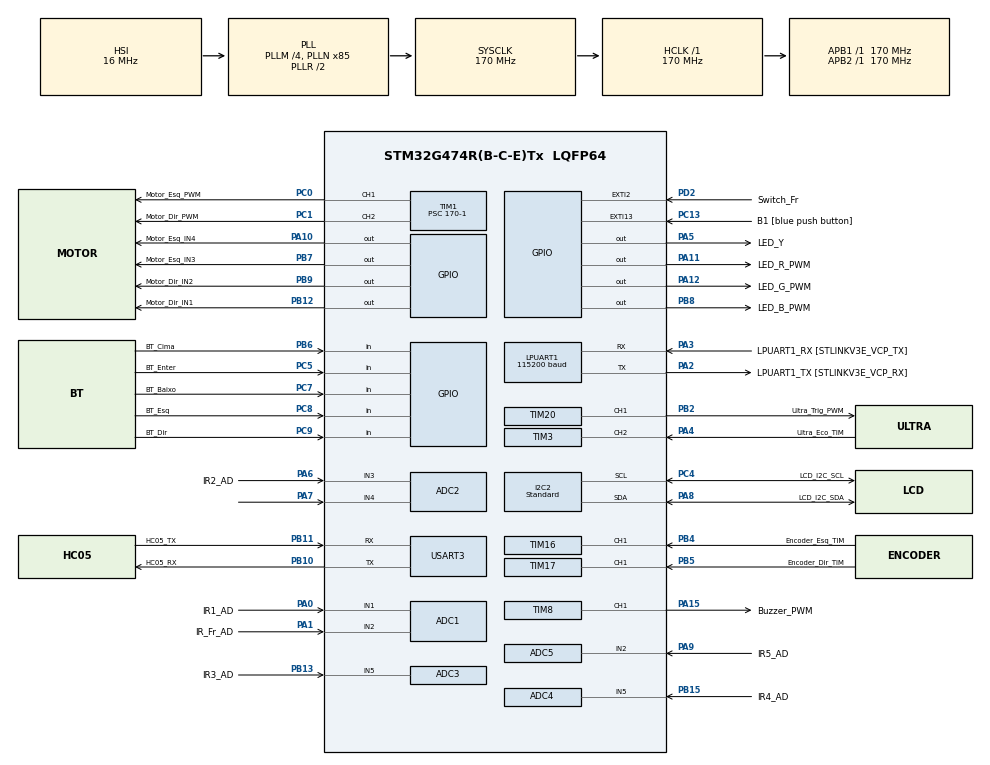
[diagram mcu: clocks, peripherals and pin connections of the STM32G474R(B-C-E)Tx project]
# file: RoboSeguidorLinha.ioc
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ADC1.Channel-0\#ChannelRegularConversion=ADC_CHANNEL_1
ADC1.Channel-1\#ChannelRegularConversion=ADC_CHANNEL_2
ADC1.ContinuousConvMode=ENABLE
ADC1.DMAContinuousRequests=ENABLE
ADC1.EOCSelection=ADC_EOC_SEQ_CONV
ADC1.NbrOfConversion=2
ADC1.NbrOfConversionFlag=1
ADC1.OffsetNumber-0\#ChannelRegularConversion=ADC_OFFSET_NONE
ADC1.OffsetNumber-1\#ChannelRegularConversion=ADC_OFFSET_NONE
ADC1.Overrun=ADC_OVR_DATA_OVERWRITTEN
ADC1.OversamplingMode=ENABLE
ADC1.Rank-0\#ChannelRegularConversion=1
ADC1.Rank-1\#ChannelRegularConversion=2
ADC1.Ratio=ADC_OVERSAMPLING_RATIO_128
ADC1.RightBitShift=ADC_RIGHTBITSHIFT_7
ADC1.SamplingTime-0\#ChannelRegularConversion=ADC_SAMPLETIME_47CYCLES_5
ADC1.SamplingTime-1\#ChannelRegularConversion=ADC_SAMPLETIME_47CYCLES_5
ADC1.master=1
ADC2.Channel-1\#ChannelRegularConversion=ADC_CHANNEL_3
ADC2.ContinuousConvMode=DISABLE
ADC2.DMAContinuousRequests=ENABLE
ADC2.EOCSelection=ADC_EOC_SINGLE_CONV
ADC2.NbrOfConversion=1
ADC2.NbrOfConversionFlag=1
ADC2.OffsetNumber-1\#ChannelRegularConversion=ADC_OFFSET_NONE
ADC2.OversamplingMode=ENABLE
ADC2.Rank-1\#ChannelRegularConversion=1
ADC2.Ratio=ADC_OVERSAMPLING_RATIO_128
ADC2.RightBitShift=ADC_RIGHTBITSHIFT_3
ADC2.SamplingTime-1\#ChannelRegularConversion=ADC_SAMPLETIME_47CYCLES_5
ADC3.Channel-0\#ChannelRegularConversion=ADC_CHANNEL_5
ADC3.ContinuousConvMode=ENABLE
ADC3.DMAContinuousRequests=ENABLE
ADC3.EOCSelection=ADC_EOC_SEQ_CONV
ADC3.NbrOfConversionFlag=1
ADC3.OffsetNumber-0\#ChannelRegularConversion=ADC_OFFSET_NONE
ADC3.OversamplingMode=ENABLE
ADC3.Rank-0\#ChannelRegularConversion=1
ADC3.Ratio=ADC_OVERSAMPLING_RATIO_128
ADC3.RightBitShift=ADC_RIGHTBITSHIFT_7
ADC3.SamplingTime-0\#ChannelRegularConversion=ADC_SAMPLETIME_47CYCLES_5
ADC3.master=1
ADC4.Channel-0\#ChannelRegularConversion=ADC_CHANNEL_5
ADC4.ContinuousConvMode=ENABLE
ADC4.DMAContinuousRequests=ENABLE
ADC4.NbrOfConversionFlag=1
ADC4.OffsetNumber-0\#ChannelRegularConversion=ADC_OFFSET_NONE
ADC4.OversamplingMode=ENABLE
ADC4.Rank-0\#ChannelRegularConversion=1
ADC4.Ratio=ADC_OVERSAMPLING_RATIO_128
ADC4.RightBitShift=ADC_RIGHTBITSHIFT_7
ADC4.SamplingTime-0\#ChannelRegularConversion=ADC_SAMPLETIME_2CYCLES_5
ADC5.Channel-0\#ChannelRegularConversion=ADC_CHANNEL_2
ADC5.ContinuousConvMode=ENABLE
ADC5.DMAContinuousRequests=ENABLE
ADC5.EOCSelection=ADC_EOC_SEQ_CONV
ADC5.NbrOfConversionFlag=1
ADC5.OffsetNumber-0\#ChannelRegularConversion=ADC_OFFSET_NONE
ADC5.OversamplingMode=ENABLE
ADC5.Rank-0\#ChannelRegularConversion=1
ADC5.Ratio=ADC_OVERSAMPLING_RATIO_128
ADC5.RightBitShift=ADC_RIGHTBITSHIFT_7
ADC5.SamplingTime-0\#ChannelRegularConversion=ADC_SAMPLETIME_47CYCLES_5
Dma.ADC1.0.Direction=DMA_PERIPH_TO_MEMORY
Dma.ADC1.0.EventEnable=DISABLE
Dma.ADC1.0.Instance=DMA1_Channel1
Dma.ADC1.0.MemDataAlignment=DMA_MDATAALIGN_HALFWORD
Dma.ADC1.0.MemInc=DMA_MINC_ENABLE
Dma.ADC1.0.Mode=DMA_CIRCULAR
Dma.ADC1.0.PeriphDataAlignment=DMA_PDATAALIGN_HALFWORD
Dma.ADC1.0.PeriphInc=DMA_PINC_DISABLE
Dma.ADC1.0.Polarity=HAL_DMAMUX_REQ_GEN_RISING
Dma.ADC1.0.Priority=DMA_PRIORITY_LOW
Dma.ADC1.0.RequestNumber=1
Dma.ADC1.0.SignalID=NONE
Dma.ADC1.0.SyncEnable=DISABLE
Dma.ADC1.0.SyncPolarity=HAL_DMAMUX_SYNC_NO_EVENT
Dma.ADC1.0.SyncRequestNumber=1
Dma.ADC1.0.SyncSignalID=NONE
Dma.ADC2.3.Direction=DMA_PERIPH_TO_MEMORY
Dma.ADC2.3.EventEnable=DISABLE
Dma.ADC2.3.Instance=DMA1_Channel2
Dma.ADC2.3.MemDataAlignment=DMA_MDATAALIGN_HALFWORD
Dma.ADC2.3.MemInc=DMA_MINC_ENABLE
Dma.ADC2.3.Mode=DMA_CIRCULAR
Dma.ADC2.3.PeriphDataAlignment=DMA_PDATAALIGN_HALFWORD
Dma.ADC2.3.PeriphInc=DMA_PINC_DISABLE
Dma.ADC2.3.Polarity=HAL_DMAMUX_REQ_GEN_RISING
Dma.ADC2.3.Priority=DMA_PRIORITY_LOW
Dma.ADC2.3.RequestNumber=1
Dma.ADC2.3.SignalID=NONE
Dma.ADC2.3.SyncEnable=DISABLE
Dma.ADC2.3.SyncPolarity=HAL_DMAMUX_SYNC_NO_EVENT
Dma.ADC2.3.SyncRequestNumber=1
Dma.ADC2.3.SyncSignalID=NONE
Dma.ADC3.1.Direction=DMA_PERIPH_TO_MEMORY
Dma.ADC3.1.EventEnable=DISABLE
Dma.ADC3.1.Instance=DMA1_Channel3
Dma.ADC3.1.MemDataAlignment=DMA_MDATAALIGN_HALFWORD
Dma.ADC3.1.MemInc=DMA_MINC_ENABLE
Dma.ADC3.1.Mode=DMA_CIRCULAR
Dma.ADC3.1.PeriphDataAlignment=DMA_PDATAALIGN_HALFWORD
Dma.ADC3.1.PeriphInc=DMA_PINC_DISABLE
Dma.ADC3.1.Polarity=HAL_DMAMUX_REQ_GEN_RISING
Dma.ADC3.1.Priority=DMA_PRIORITY_LOW
Dma.ADC3.1.RequestNumber=1
Dma.ADC3.1.SignalID=NONE
Dma.ADC3.1.SyncEnable=DISABLE
Dma.ADC3.1.SyncPolarity=HAL_DMAMUX_SYNC_NO_EVENT
Dma.ADC3.1.SyncRequestNumber=1
Dma.ADC3.1.SyncSignalID=NONE
Dma.ADC4.4.Direction=DMA_PERIPH_TO_MEMORY
Dma.ADC4.4.EventEnable=DISABLE
Dma.ADC4.4.Instance=DMA1_Channel4
Dma.ADC4.4.MemDataAlignment=DMA_MDATAALIGN_HALFWORD
Dma.ADC4.4.MemInc=DMA_MINC_ENABLE
Dma.ADC4.4.Mode=DMA_CIRCULAR
Dma.ADC4.4.PeriphDataAlignment=DMA_PDATAALIGN_HALFWORD
Dma.ADC4.4.PeriphInc=DMA_PINC_DISABLE
Dma.ADC4.4.Polarity=HAL_DMAMUX_REQ_GEN_RISING
Dma.ADC4.4.Priority=DMA_PRIORITY_LOW
Dma.ADC4.4.RequestNumber=1
Dma.ADC4.4.SignalID=NONE
Dma.ADC4.4.SyncEnable=DISABLE
Dma.ADC4.4.SyncPolarity=HAL_DMAMUX_SYNC_NO_EVENT
Dma.ADC4.4.SyncRequestNumber=1
Dma.ADC4.4.SyncSignalID=NONE
Dma.ADC5.2.Direction=DMA_PERIPH_TO_MEMORY
Dma.ADC5.2.EventEnable=DISABLE
Dma.ADC5.2.Instance=DMA1_Channel5
Dma.ADC5.2.MemDataAlignment=DMA_MDATAALIGN_HALFWORD
Dma.ADC5.2.MemInc=DMA_MINC_ENABLE
Dma.ADC5.2.Mode=DMA_CIRCULAR
Dma.ADC5.2.PeriphDataAlignment=DMA_PDATAALIGN_HALFWORD
Dma.ADC5.2.PeriphInc=DMA_PINC_DISABLE
Dma.ADC5.2.Polarity=HAL_DMAMUX_REQ_GEN_RISING
Dma.ADC5.2.Priority=DMA_PRIORITY_LOW
Dma.ADC5.2.RequestNumber=1
Dma.ADC5.2.SignalID=NONE
Dma.ADC5.2.SyncEnable=DISABLE
Dma.ADC5.2.SyncPolarity=HAL_DMAMUX_SYNC_NO_EVENT
Dma.ADC5.2.SyncRequestNumber=1
Dma.ADC5.2.SyncSignalID=NONE
Dma.I2C2_RX.5.Direction=DMA_PERIPH_TO_MEMORY
Dma.I2C2_RX.5.EventEnable=DISABLE
Dma.I2C2_RX.5.Instance=DMA2_Channel6
Dma.I2C2_RX.5.MemDataAlignment=DMA_MDATAALIGN_BYTE
Dma.I2C2_RX.5.MemInc=DMA_MINC_ENABLE
Dma.I2C2_RX.5.Mode=DMA_NORMAL
Dma.I2C2_RX.5.PeriphDataAlignment=DMA_PDATAALIGN_BYTE
Dma.I2C2_RX.5.PeriphInc=DMA_PINC_DISABLE
Dma.I2C2_RX.5.Polarity=HAL_DMAMUX_REQ_GEN_RISING
Dma.I2C2_RX.5.Priority=DMA_PRIORITY_LOW
Dma.I2C2_RX.5.RequestNumber=1
Dma.I2C2_RX.5.SignalID=NONE
Dma.I2C2_RX.5.SyncEnable=DISABLE
Dma.I2C2_RX.5.SyncPolarity=HAL_DMAMUX_SYNC_NO_EVENT
Dma.I2C2_RX.5.SyncRequestNumber=1
Dma.I2C2_RX.5.SyncSignalID=NONE
Dma.I2C2_TX.6.Direction=DMA_MEMORY_TO_PERIPH
Dma.I2C2_TX.6.EventEnable=DISABLE
Dma.I2C2_TX.6.Instance=DMA2_Channel7
Dma.I2C2_TX.6.MemDataAlignment=DMA_MDATAALIGN_BYTE
Dma.I2C2_TX.6.MemInc=DMA_MINC_ENABLE
Dma.I2C2_TX.6.Mode=DMA_NORMAL
Dma.I2C2_TX.6.PeriphDataAlignment=DMA_PDATAALIGN_BYTE
Dma.I2C2_TX.6.PeriphInc=DMA_PINC_DISABLE
Dma.I2C2_TX.6.Polarity=HAL_DMAMUX_REQ_GEN_RISING
Dma.I2C2_TX.6.Priority=DMA_PRIORITY_LOW
Dma.I2C2_TX.6.RequestNumber=1
Dma.I2C2_TX.6.SignalID=NONE
Dma.I2C2_TX.6.SyncEnable=DISABLE
Dma.I2C2_TX.6.SyncPolarity=HAL_DMAMUX_SYNC_NO_EVENT
Dma.I2C2_TX.6.SyncRequestNumber=1
Dma.I2C2_TX.6.SyncSignalID=NONE
Dma.Request0=ADC1
Dma.Request1=ADC3
Dma.Request2=ADC5
Dma.Request3=ADC2
Dma.Request4=ADC4
Dma.Request5=I2C2_RX
Dma.Request6=I2C2_TX
FREERTOS.BinarySemaphores01=Sem_Colisao,Dynamic,NULL
FREERTOS.Mutexes01=Mutex_Sensores,Dynamic,NULL;Mutex_Odometria,Dynamic,NULL;Mutex_PID,Dynamic,NULL;Mutex_Battery,Dynamic,NULL
FREERTOS.Queues01=Queue_Comandos,16,uint16_t,0,Dynamic,NULL,NULL
FREERTOS.Tasks01=task_main,24,256,task_Main,Default,NULL,Dynamic,NULL,NULL;task_controle,40,512,task_Controle,As external,NULL,Dynamic,NULL,NULL;task_sensores,8,256,task_Sensores,As external,NULL,Dynamic,NULL,NULL;task_odometria,8,256,task_Odometria,As external,NULL,Dynamic,NULL,NULL;task_bluetooth,16,256,task_Bluetooth,As external,NULL,Dynamic,NULL,NULL;task_LVBateria,8,128,task_LvBateria,As external,NULL,Dynamic,NULL,NULL;task_Display,8,128,task_display,As external,NULL,Dynamic,NULL,NULL;task_linhas,8,128,task_Linhas,Default,NULL,Dynamic,NULL,NULL
FREERTOS.configTOTAL_HEAP_SIZE=10240
FREERTOS.configUSE_NEWLIB_REENTRANT=1
I2C2.I2C_Speed_Mode=I2C_Standard
I2C2.Timing=0x30A0A7FB
LPUART1.BaudRate=115200
LPUART1.WordLength=UART_WORDLENGTH_8B
Mcu.Family=STM32G4
Mcu.Name=STM32G474R(B-C-E)Tx
Mcu.Package=LQFP64
NVIC.ADC1_2_IRQn=true\:5\:0\:false\:false\:true\:true\:true\:true\:true
NVIC.ADC3_IRQn=true\:5\:0\:false\:false\:true\:true\:true\:true\:true
NVIC.ADC4_IRQn=true\:5\:0\:false\:false\:true\:true\:true\:true\:true
NVIC.ADC5_IRQn=true\:5\:0\:false\:false\:true\:true\:true\:true\:true
NVIC.DMA1_Channel1_IRQn=true\:5\:0\:false\:false\:true\:true\:false\:true\:true
NVIC.DMA1_Channel2_IRQn=true\:5\:0\:false\:false\:true\:true\:false\:true\:true
NVIC.DMA1_Channel3_IRQn=true\:5\:0\:false\:false\:true\:true\:false\:true\:true
NVIC.DMA1_Channel4_IRQn=true\:5\:0\:false\:false\:true\:true\:false\:true\:true
NVIC.DMA1_Channel5_IRQn=true\:5\:0\:false\:false\:true\:true\:false\:true\:true
NVIC.DMA2_Channel6_IRQn=true\:5\:0\:false\:false\:true\:true\:false\:true\:true
NVIC.DMA2_Channel7_IRQn=true\:5\:0\:false\:false\:true\:false\:false\:true\:true
NVIC.EXTI15_10_IRQn=true\:5\:0\:false\:false\:true\:true\:true\:true\:true
NVIC.EXTI2_IRQn=true\:5\:0\:false\:false\:true\:true\:true\:true\:true
NVIC.I2C2_ER_IRQn=true\:5\:0\:false\:false\:true\:true\:true\:true\:true
NVIC.I2C2_EV_IRQn=true\:5\:0\:false\:false\:true\:true\:true\:true\:true
NVIC.PriorityGroup=NVIC_PRIORITYGROUP_4
NVIC.TIM1_TRG_COM_TIM17_IRQn=true\:5\:0\:false\:false\:true\:true\:true\:true\:true
NVIC.TIM1_UP_TIM16_IRQn=true\:5\:0\:false\:false\:true\:true\:true\:true\:true
NVIC.TIM3_IRQn=true\:5\:0\:false\:false\:true\:true\:true\:true\:true
NVIC.TIM6_DAC_IRQn=true\:15\:0\:false\:false\:true\:false\:false\:true\:true
NVIC.TimeBase=TIM6_DAC_IRQn
NVIC.TimeBaseIP=TIM6
NVIC.USART3_IRQn=true\:5\:0\:false\:false\:true\:true\:true\:true\:true
PA0.GPIO_Label=IR1_AD
PA0.Mode=IN1-Single-Ended
PA0.Signal=ADC1_IN1
PA1.GPIO_Label=IR_Fr_AD
PA1.Mode=IN2-Single-Ended
PA1.Signal=ADC1_IN2
PA10.GPIO_Label=Motor_Esq_IN4
PA10.Signal=GPIO_Output
PA11.GPIO_Label=LED_R_PWM
PA11.Signal=GPIO_Output
PA12.GPIO_Label=LED_G_PWM
PA12.Signal=GPIO_Output
PA13.GPIO_Label=T_SWDIO
PA13.Mode=Serial_Wire
PA13.Signal=SYS_JTMS-SWDIO
PA14.GPIO_Label=T_SWCLK
PA14.Mode=Serial_Wire
PA14.Signal=SYS_JTCK-SWCLK
PA15.GPIO_Label=Buzzer_PWM
PA15.Signal=S_TIM8_CH1
PA2.GPIO_Label=LPUART1_TX [STLINKV3E_VCP_RX]
PA2.Mode=Asynchronous
PA2.Signal=LPUART1_TX
PA3.GPIO_Label=LPUART1_RX [STLINKV3E_VCP_TX]
PA3.Mode=Asynchronous
PA3.Signal=LPUART1_RX
PA4.GPIO_Label=Ultra_Eco_TIM
PA4.Signal=S_TIM3_CH2
PA5.GPIO_Label=LED_Y
PA5.Signal=GPIO_Output
PA6.GPIO_Label=IR2_AD
PA6.Mode=IN3-Single-Ended
PA6.Signal=ADC2_IN3
PA7.Signal=SharedAnalog_PA7
PA8.GPIO_Label=LCD_I2C_SDA
PA8.Mode=I2C
PA8.Signal=I2C2_SDA
PA9.GPIO_Label=IR5_AD
PA9.Mode=IN2-Single-Ended
PA9.Signal=ADC5_IN2
PB10.GPIO_Label=HC05_RX
PB10.Mode=Asynchronous
PB10.Signal=USART3_TX
PB11.GPIO_Label=HC05_TX
PB11.Mode=Asynchronous
PB11.Signal=USART3_RX
PB12.GPIO_Label=Motor_Dir_IN1
PB12.Signal=GPIO_Output
PB13.GPIO_Label=IR3_AD
PB13.Mode=IN5-Single-Ended
PB13.Signal=ADC3_IN5
PB15.GPIO_Label=IR4_AD
PB15.Mode=IN5-Single-Ended
PB15.Signal=ADC4_IN5
PB2.GPIO_Label=Ultra_Trig_PWM
PB2.Mode=Output Compare1 CH1
PB2.Signal=TIM20_CH1
PB3.GPIO_Label=T_SWO
PB3.Signal=SYS_JTDO-SWO
PB4.GPIO_Label=Encoder_Esq_TIM
PB4.Signal=S_TIM16_CH1
PB5.GPIO_Label=Encoder_Dir_TIM
PB5.Signal=S_TIM17_CH1
PB6.GPIO_Label=BT_Cima
PB6.Signal=GPIO_Input
PB7.GPIO_Label=Motor_Esq_IN3
PB7.Signal=GPIO_Output
PB8-BOOT0.GPIO_Label=LED_B_PWM
PB8-BOOT0.Signal=GPIO_Output
PB9.GPIO_Label=Motor_Dir_IN2
PB9.Signal=GPIO_Output
PC0.GPIO_Label=Motor_Esq_PWM
PC0.Signal=S_TIM1_CH1
PC1.GPIO_Label=Motor_Dir_PWM
PC1.Signal=S_TIM1_CH2
PC13.GPIO_Label=B1 [blue push button]
PC13.Signal=GPXTI13
PC14-OSC32_IN.Mode=LSE-External-Oscillator
PC14-OSC32_IN.Signal=RCC_OSC32_IN
PC15-OSC32_OUT.Mode=LSE-External-Oscillator
PC15-OSC32_OUT.Signal=RCC_OSC32_OUT
PC4.GPIO_Label=LCD_I2C_SCL
PC4.Mode=I2C
PC4.Signal=I2C2_SCL
PC5.GPIO_Label=BT_Enter
PC5.GPIO_PuPd=GPIO_PULLUP
PC5.Signal=GPIO_Input
PC7.GPIO_Label=BT_Baixo
PC7.Signal=GPIO_Input
PC8.GPIO_Label=BT_Esq
PC8.Signal=GPIO_Input
PC9.GPIO_Label=BT_Dir
PC9.Signal=GPIO_Input
PD2.GPIO_Label=Switch_Fr
PD2.GPIO_ModeDefaultEXTI=GPIO_MODE_IT_FALLING
PD2.GPIO_PuPd=GPIO_PULLUP
PD2.Signal=GPXTI2
PF0-OSC_IN.Mode=HSE-External-Oscillator
PF0-OSC_IN.Signal=RCC_OSC_IN
PF1-OSC_OUT.Mode=HSE-External-Oscillator
PF1-OSC_OUT.Signal=RCC_OSC_OUT
ProjectManager.HeapSize=0x200
ProjectManager.StackSize=0x400
ProjectManager.TargetToolchain=STM32CubeIDE
RCC.ADC12Freq_Value=170000000
RCC.ADC345Freq_Value=170000000
RCC.AHBFreq_Value=170000000
RCC.APB1Freq_Value=170000000
RCC.APB1TimFreq_Value=170000000
RCC.APB2Freq_Value=170000000
RCC.APB2TimFreq_Value=170000000
RCC.CortexFreq_Value=170000000
RCC.EXTERNAL_CLOCK_VALUE=12288000
RCC.HCLKFreq_Value=170000000
RCC.HSE_VALUE=24000000
RCC.HSI48_VALUE=48000000
RCC.HSI_VALUE=16000000
RCC.PLLM=RCC_PLLM_DIV4
RCC.PLLN=85
RCC.RTCClockSelection=RCC_RTCCLKSOURCE_LSE
RCC.SYSCLKFreq_VALUE=170000000
RCC.SYSCLKSource=RCC_SYSCLKSOURCE_PLLCLK
RCC.USBFreq_Value=170000000
RCC.VCOOutputFreq_Value=340000000
SH.S_TIM16_CH1.0=TIM16_CH1,Input_Capture1_from_TI1
SH.S_TIM17_CH1.0=TIM17_CH1,Input_Capture1_from_TI1
SH.S_TIM1_CH1.0=TIM1_CH1,PWM Generation1 CH1
SH.S_TIM1_CH2.0=TIM1_CH2,PWM Generation2 CH2
SH.S_TIM3_CH2.0=TIM3_CH2,Input_Capture2_from_TI2
SH.S_TIM8_CH1.0=TIM8_CH1,PWM Generation1 CH1
SH.SharedAnalog_PA7.0=ADC2_IN4,IN4-Single-Ended
SH.SharedAnalog_PA7.1=OPAMP2_VINP,PGA_Internally_Connected
SH.SharedAnalog_PA7.2=OPAMP1_VINP,PGA_Internally_Connected
TIM1.Channel-PWM\ Generation1\ CH1=TIM_CHANNEL_1
TIM1.Channel-PWM\ Generation2\ CH2=TIM_CHANNEL_2
TIM1.PeriodNoDither=100-1
TIM1.Prescaler=170-1
TIM16.Channel=TIM_CHANNEL_1
TIM17.Channel=TIM_CHANNEL_1
TIM20.Channel-Output\ Compare1\ CH1=TIM_CHANNEL_1
TIM3.Channel-Input_Capture2_from_TI2=TIM_CHANNEL_2
TIM3.PeriodNoDither=100-1
TIM3.Prescaler=170-1
TIM8.Channel-PWM\ Generation1\ CH1=TIM_CHANNEL_1
TIM8.PeriodNoDither=1000-1
TIM8.Prescaler=170-1
USART3.VirtualMode-Asynchronous=VM_ASYNC
VP_ADC2_OPAMP_INTERNAL2.Mode=IN-OPAMP2
VP_FREERTOS_VS_CMSIS_V2.Mode=CMSIS_V2
VP_SYS_VS_DBSignals.Mode=DisableDeadBatterySignals
VP_SYS_VS_tim6.Mode=TIM6
VP_TIM16_VS_ClockSourceINT.Mode=Enable_Timer
VP_TIM17_VS_ClockSourceINT.Mode=Enable_Timer
VP_TIM1_VS_ClockSourceINT.Mode=Internal
VP_TIM20_VS_ClockSourceINT.Mode=Internal
VP_TIM2_VS_ClockSourceINT.Mode=Internal
VP_TIM3_VS_ClockSourceINT.Mode=Internal
VP_TIM8_VS_ClockSourceINT.Mode=Internal
board=NUCLEO-G474RE

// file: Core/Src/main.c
/* USER CODE BEGIN Header */
/**
  ******************************************************************************
  * @file           : main.c
  * @brief          : Main program body
  ******************************************************************************
  * @attention
  *
  * Copyright (c) 2026 STMicroelectronics.
  * All rights reserved.
  *
  * This software is licensed under terms that can be found in the LICENSE file
  * in the root directory of this software component.
  * If no LICENSE file comes with this software, it is provided AS-IS.
  *
  ******************************************************************************
  */
/* USER CODE END Header */
#include "main.h"
#include "cmsis_os.h"

/* USER CODE BEGIN Includes */
#include "lineSensors_v2.h"
#include "motorEncoder.h"

/* USER CODE END Includes */

ADC_HandleTypeDef hadc1;
ADC_HandleTypeDef hadc2;
ADC_HandleTypeDef hadc3;
ADC_HandleTypeDef hadc4;
ADC_HandleTypeDef hadc5;
DMA_HandleTypeDef hdma_adc1;
DMA_HandleTypeDef hdma_adc2;
DMA_HandleTypeDef hdma_adc3;
DMA_HandleTypeDef hdma_adc4;
DMA_HandleTypeDef hdma_adc5;

I2C_HandleTypeDef hi2c2;
DMA_HandleTypeDef hdma_i2c2_rx;
DMA_HandleTypeDef hdma_i2c2_tx;

UART_HandleTypeDef hlpuart1;
UART_HandleTypeDef huart3;

OPAMP_HandleTypeDef hopamp1;
OPAMP_HandleTypeDef hopamp2;

TIM_HandleTypeDef htim1;
TIM_HandleTypeDef htim2;
TIM_HandleTypeDef htim3;
TIM_HandleTypeDef htim8;
TIM_HandleTypeDef htim16;
TIM_HandleTypeDef htim17;
TIM_HandleTypeDef htim20;

/* Definitions for task_main */
osThreadId_t task_mainHandle;
const osThreadAttr_t task_main_attributes = {
  .name = "task_main",
  .priority = (osPriority_t) osPriorityNormal,
  .stack_size = 256 * 4
};
/* Definitions for task_controle */
osThreadId_t task_controleHandle;
const osThreadAttr_t task_controle_attributes = {
  .name = "task_controle",
  .priority = (osPriority_t) osPriorityHigh,
  .stack_size = 512 * 4
};
/* Definitions for task_sensores */
osThreadId_t task_sensoresHandle;
const osThreadAttr_t task_sensores_attributes = {
  .name = "task_sensores",
  .priority = (osPriority_t) osPriorityLow,
  .stack_size = 256 * 4
};
/* Definitions for task_odometria */
osThreadId_t task_odometriaHandle;
const osThreadAttr_t task_odometria_attributes = {
  .name = "task_odometria",
  .priority = (osPriority_t) osPriorityLow,
  .stack_size = 256 * 4
};
/* Definitions for task_bluetooth */
osThreadId_t task_bluetoothHandle;
const osThreadAttr_t task_bluetooth_attributes = {
  .name = "task_bluetooth",
  .priority = (osPriority_t) osPriorityBelowNormal,
  .stack_size = 256 * 4
};
/* Definitions for task_LVBateria */
osThreadId_t task_LVBateriaHandle;
const osThreadAttr_t task_LVBateria_attributes = {
  .name = "task_LVBateria",
  .priority = (osPriority_t) osPriorityLow,
  .stack_size = 128 * 4
};
/* Definitions for task_Display */
osThreadId_t task_DisplayHandle;
const osThreadAttr_t task_Display_attributes = {
  .name = "task_Display",
  .priority = (osPriority_t) osPriorityLow,
  .stack_size = 128 * 4
};
/* Definitions for task_linhas */
osThreadId_t task_linhasHandle;
const osThreadAttr_t task_linhas_attributes = {
  .name = "task_linhas",
  .priority = (osPriority_t) osPriorityLow,
  .stack_size = 128 * 4
};
/* Definitions for Queue_Comandos */
osMessageQueueId_t Queue_ComandosHandle;
const osMessageQueueAttr_t Queue_Comandos_attributes = {
  .name = "Queue_Comandos"
};
/* Definitions for Mutex_Sensores */
osMutexId_t Mutex_SensoresHandle;
const osMutexAttr_t Mutex_Sensores_attributes = {
  .name = "Mutex_Sensores"
};
/* Definitions for Mutex_Odometria */
osMutexId_t Mutex_OdometriaHandle;
const osMutexAttr_t Mutex_Odometria_attributes = {
  .name = "Mutex_Odometria"
};
/* Definitions for Mutex_PID */
osMutexId_t Mutex_PIDHandle;
const osMutexAttr_t Mutex_PID_attributes = {
  .name = "Mutex_PID"
};
/* Definitions for Mutex_Battery */
osMutexId_t Mutex_BatteryHandle;
const osMutexAttr_t Mutex_Battery_attributes = {
  .name = "Mutex_Battery"
};
/* Definitions for Sem_Colisao */
osSemaphoreId_t Sem_ColisaoHandle;
const osSemaphoreAttr_t Sem_Colisao_attributes = {
  .name = "Sem_Colisao"
};

void SystemClock_Config(void);
static void MX_GPIO_Init(void);
static void MX_DMA_Init(void);
static void MX_LPUART1_UART_Init(void);
static void MX_ADC1_Init(void);
static void MX_ADC3_Init(void);
static void MX_TIM2_Init(void);
static void MX_ADC2_Init(void);
static void MX_ADC5_Init(void);
static void MX_TIM16_Init(void);
static void MX_TIM17_Init(void);
static void MX_I2C2_Init(void);
static void MX_USART3_UART_Init(void);
static void MX_TIM1_Init(void);
static void MX_TIM3_Init(void);
static void MX_TIM8_Init(void);
static void MX_TIM20_Init(void);
static void MX_ADC4_Init(void);
static void MX_OPAMP2_Init(void);
static void MX_OPAMP1_Init(void);
void task_Main(void *argument);
extern void task_Controle(void *argument);
extern void task_Sensores(void *argument);
extern void task_Odometria(void *argument);
extern void task_Bluetooth(void *argument);
extern void task_LvBateria(void *argument);
extern void task_display(void *argument);
void task_Linhas(void *argument);

int main(void)
{

  /* MCU Configuration--------------------------------------------------------*/

  /* Reset of all peripherals, Initializes the Flash interface and the Systick. */
  HAL_Init();

  /* Configure the system clock */
  SystemClock_Config();

  /* Initialize all configured peripherals */
  MX_GPIO_Init();
  MX_DMA_Init();
  MX_LPUART1_UART_Init();
  MX_ADC1_Init();
  MX_ADC3_Init();
  MX_TIM2_Init();
  MX_ADC2_Init();
  MX_ADC5_Init();
  MX_TIM16_Init();
  MX_TIM17_Init();
  MX_I2C2_Init();
  MX_USART3_UART_Init();
  MX_TIM1_Init();
  MX_TIM3_Init();
  MX_TIM8_Init();
  MX_TIM20_Init();
  MX_ADC4_Init();
  MX_OPAMP2_Init();
  MX_OPAMP1_Init();
  /* USER CODE BEGIN 2 */
  HAL_TIM_PWM_Start(&htim1, TIM_CHANNEL_1);  // Motor esquerdo
  HAL_TIM_PWM_Start(&htim1, TIM_CHANNEL_2);  // Motor direito
  HAL_TIM_PWM_Start(&htim8, TIM_CHANNEL_1);  // Buzzer

  /* USER CODE END 2 */

  /* Init scheduler */
  osKernelInitialize();
  /* Create the mutex(es) */
  /* creation of Mutex_Sensores */
  Mutex_SensoresHandle = osMutexNew(&Mutex_Sensores_attributes);

  /* creation of Mutex_Odometria */
  Mutex_OdometriaHandle = osMutexNew(&Mutex_Odometria_attributes);

  /* creation of Mutex_PID */
  Mutex_PIDHandle = osMutexNew(&Mutex_PID_attributes);

  /* creation of Mutex_Battery */
  Mutex_BatteryHandle = osMutexNew(&Mutex_Battery_attributes);

  /* Create the semaphores(s) */
  /* creation of Sem_Colisao */
  Sem_ColisaoHandle = osSemaphoreNew(1, 1, &Sem_Colisao_attributes);

  /* Create the queue(s) */
  /* creation of Queue_Comandos */
  Queue_ComandosHandle = osMessageQueueNew (16, sizeof(uint16_t), &Queue_Comandos_attributes);

  /* Create the thread(s) */
  /* creation of task_main */
  task_mainHandle = osThreadNew(task_Main, NULL, &task_main_attributes);

  /* creation of task_controle */
  task_controleHandle = osThreadNew(task_Controle, NULL, &task_controle_attributes);

  /* creation of task_sensores */
  task_sensoresHandle = osThreadNew(task_Sensores, NULL, &task_sensores_attributes);

  /* creation of task_odometria */
  task_odometriaHandle = osThreadNew(task_Odometria, NULL, &task_odometria_attributes);

  /* creation of task_bluetooth */
  task_bluetoothHandle = osThreadNew(task_Bluetooth, NULL, &task_bluetooth_attributes);

  /* creation of task_LVBateria */
  task_LVBateriaHandle = osThreadNew(task_LvBateria, NULL, &task_LVBateria_attributes);

  /* creation of task_Display */
  task_DisplayHandle = osThreadNew(task_display, NULL, &task_Display_attributes);

  /* creation of task_linhas */
  task_linhasHandle = osThreadNew(task_Linhas, NULL, &task_linhas_attributes);

  /* Start scheduler */
  osKernelStart();
  /* We should never get here as control is now taken by the scheduler */
  /* Infinite loop */
  while (1)
  {

  }
}

void SystemClock_Config(void)
{
  RCC_OscInitTypeDef RCC_OscInitStruct = {0};
  RCC_ClkInitTypeDef RCC_ClkInitStruct = {0};

  /** Configure the main internal regulator output voltage
  */
  HAL_PWREx_ControlVoltageScaling(PWR_REGULATOR_VOLTAGE_SCALE1_BOOST);

  /** Initializes the RCC Oscillators according to the specified parameters
  * in the RCC_OscInitTypeDef structure.
  */
  RCC_OscInitStruct.OscillatorType = RCC_OSCILLATORTYPE_HSI;
  RCC_OscInitStruct.HSIState = RCC_HSI_ON;
  RCC_OscInitStruct.HSICalibrationValue = RCC_HSICALIBRATION_DEFAULT;
  RCC_OscInitStruct.PLL.PLLState = RCC_PLL_ON;
  RCC_OscInitStruct.PLL.PLLSource = RCC_PLLSOURCE_HSI;
  RCC_OscInitStruct.PLL.PLLM = RCC_PLLM_DIV4;
  RCC_OscInitStruct.PLL.PLLN = 85;
  RCC_OscInitStruct.PLL.PLLP = RCC_PLLP_DIV2;
  RCC_OscInitStruct.PLL.PLLQ = RCC_PLLQ_DIV2;
  RCC_OscInitStruct.PLL.PLLR = RCC_PLLR_DIV2;
  if (HAL_RCC_OscConfig(&RCC_OscInitStruct) != HAL_OK)
  {
    Error_Handler();
  }

  /** Initializes the CPU, AHB and APB buses clocks
  */
  RCC_ClkInitStruct.ClockType = RCC_CLOCKTYPE_HCLK|RCC_CLOCKTYPE_SYSCLK
                              |RCC_CLOCKTYPE_PCLK1|RCC_CLOCKTYPE_PCLK2;
  RCC_ClkInitStruct.SYSCLKSource = RCC_SYSCLKSOURCE_PLLCLK;
  RCC_ClkInitStruct.AHBCLKDivider = RCC_SYSCLK_DIV1;
  RCC_ClkInitStruct.APB1CLKDivider = RCC_HCLK_DIV1;
  RCC_ClkInitStruct.APB2CLKDivider = RCC_HCLK_DIV1;

  if (HAL_RCC_ClockConfig(&RCC_ClkInitStruct, FLASH_LATENCY_4) != HAL_OK)
  {
    Error_Handler();
  }
}

static void MX_ADC1_Init(void)
{

  ADC_MultiModeTypeDef multimode = {0};
  ADC_ChannelConfTypeDef sConfig = {0};

  /** Common config
  */
  hadc1.Instance = ADC1;
  hadc1.Init.ClockPrescaler = ADC_CLOCK_SYNC_PCLK_DIV4;
  hadc1.Init.Resolution = ADC_RESOLUTION_12B;
  hadc1.Init.DataAlign = ADC_DATAALIGN_RIGHT;
  hadc1.Init.GainCompensation = 0;
  hadc1.Init.ScanConvMode = ADC_SCAN_ENABLE;
  hadc1.Init.EOCSelection = ADC_EOC_SEQ_CONV;
  hadc1.Init.LowPowerAutoWait = DISABLE;
  hadc1.Init.ContinuousConvMode = ENABLE;
  hadc1.Init.NbrOfConversion = 2;
  hadc1.Init.DiscontinuousConvMode = DISABLE;
  hadc1.Init.ExternalTrigConv = ADC_SOFTWARE_START;
  hadc1.Init.ExternalTrigConvEdge = ADC_EXTERNALTRIGCONVEDGE_NONE;
  hadc1.Init.DMAContinuousRequests = ENABLE;
  hadc1.Init.Overrun = ADC_OVR_DATA_OVERWRITTEN;
  hadc1.Init.OversamplingMode = ENABLE;
  hadc1.Init.Oversampling.Ratio = ADC_OVERSAMPLING_RATIO_128;
  hadc1.Init.Oversampling.RightBitShift = ADC_RIGHTBITSHIFT_7;
  hadc1.Init.Oversampling.TriggeredMode = ADC_TRIGGEREDMODE_SINGLE_TRIGGER;
  hadc1.Init.Oversampling.OversamplingStopReset = ADC_REGOVERSAMPLING_CONTINUED_MODE;
  if (HAL_ADC_Init(&hadc1) != HAL_OK)
  {
    Error_Handler();
  }

  /** Configure the ADC multi-mode
  */
  multimode.Mode = ADC_MODE_INDEPENDENT;
  if (HAL_ADCEx_MultiModeConfigChannel(&hadc1, &multimode) != HAL_OK)
  {
    Error_Handler();
  }

  /** Configure Regular Channel
  */
  sConfig.Channel = ADC_CHANNEL_1;
  sConfig.Rank = ADC_REGULAR_RANK_1;
  sConfig.SamplingTime = ADC_SAMPLETIME_47CYCLES_5;
  sConfig.SingleDiff = ADC_SINGLE_ENDED;
  sConfig.OffsetNumber = ADC_OFFSET_NONE;
  sConfig.Offset = 0;
  if (HAL_ADC_ConfigChannel(&hadc1, &sConfig) != HAL_OK)
  {
    Error_Handler();
  }

  /** Configure Regular Channel
  */
  sConfig.Channel = ADC_CHANNEL_2;
  sConfig.Rank = ADC_REGULAR_RANK_2;
  if (HAL_ADC_ConfigChannel(&hadc1, &sConfig) != HAL_OK)
  {
    Error_Handler();
  }

}

static void MX_ADC2_Init(void)
{

  ADC_ChannelConfTypeDef sConfig = {0};

  /** Common config
  */
  hadc2.Instance = ADC2;
  hadc2.Init.ClockPrescaler = ADC_CLOCK_SYNC_PCLK_DIV4;
  hadc2.Init.Resolution = ADC_RESOLUTION_12B;
  hadc2.Init.DataAlign = ADC_DATAALIGN_RIGHT;
  hadc2.Init.GainCompensation = 0;
  hadc2.Init.ScanConvMode = ADC_SCAN_DISABLE;
  hadc2.Init.EOCSelection = ADC_EOC_SINGLE_CONV;
  hadc2.Init.LowPowerAutoWait = DISABLE;
  hadc2.Init.ContinuousConvMode = DISABLE;
  hadc2.Init.NbrOfConversion = 1;
  hadc2.Init.DiscontinuousConvMode = DISABLE;
  hadc2.Init.ExternalTrigConv = ADC_SOFTWARE_START;
  hadc2.Init.ExternalTrigConvEdge = ADC_EXTERNALTRIGCONVEDGE_NONE;
  hadc2.Init.DMAContinuousRequests = ENABLE;
  hadc2.Init.Overrun = ADC_OVR_DATA_PRESERVED;
  hadc2.Init.OversamplingMode = ENABLE;
  hadc2.Init.Oversampling.Ratio = ADC_OVERSAMPLING_RATIO_128;
  hadc2.Init.Oversampling.RightBitShift = ADC_RIGHTBITSHIFT_3;
  hadc2.Init.Oversampling.TriggeredMode = ADC_TRIGGEREDMODE_SINGLE_TRIGGER;
  hadc2.Init.Oversampling.OversamplingStopReset = ADC_REGOVERSAMPLING_CONTINUED_MODE;
  if (HAL_ADC_Init(&hadc2) != HAL_OK)
  {
    Error_Handler();
  }

  /** Configure Regular Channel
  */
  sConfig.Channel = ADC_CHANNEL_3;
  sConfig.Rank = ADC_REGULAR_RANK_1;
  sConfig.SamplingTime = ADC_SAMPLETIME_47CYCLES_5;
  sConfig.SingleDiff = ADC_SINGLE_ENDED;
  sConfig.OffsetNumber = ADC_OFFSET_NONE;
  sConfig.Offset = 0;
  if (HAL_ADC_ConfigChannel(&hadc2, &sConfig) != HAL_OK)
  {
    Error_Handler();
  }

}

static void MX_ADC3_Init(void)
{

  ADC_MultiModeTypeDef multimode = {0};
  ADC_ChannelConfTypeDef sConfig = {0};

  /** Common config
  */
  hadc3.Instance = ADC3;
  hadc3.Init.ClockPrescaler = ADC_CLOCK_SYNC_PCLK_DIV4;
  hadc3.Init.Resolution = ADC_RESOLUTION_12B;
  hadc3.Init.DataAlign = ADC_DATAALIGN_RIGHT;
  hadc3.Init.GainCompensation = 0;
  hadc3.Init.ScanConvMode = ADC_SCAN_DISABLE;
  hadc3.Init.EOCSelection = ADC_EOC_SEQ_CONV;
  hadc3.Init.LowPowerAutoWait = DISABLE;
  hadc3.Init.ContinuousConvMode = ENABLE;
  hadc3.Init.NbrOfConversion = 1;
  hadc3.Init.DiscontinuousConvMode = DISABLE;
  hadc3.Init.ExternalTrigConv = ADC_SOFTWARE_START;
  hadc3.Init.ExternalTrigConvEdge = ADC_EXTERNALTRIGCONVEDGE_NONE;
  hadc3.Init.DMAContinuousRequests = ENABLE;
  hadc3.Init.Overrun = ADC_OVR_DATA_PRESERVED;
  hadc3.Init.OversamplingMode = ENABLE;
  hadc3.Init.Oversampling.Ratio = ADC_OVERSAMPLING_RATIO_128;
  hadc3.Init.Oversampling.RightBitShift = ADC_RIGHTBITSHIFT_7;
  hadc3.Init.Oversampling.TriggeredMode = ADC_TRIGGEREDMODE_SINGLE_TRIGGER;
  hadc3.Init.Oversampling.OversamplingStopReset = ADC_REGOVERSAMPLING_CONTINUED_MODE;
  if (HAL_ADC_Init(&hadc3) != HAL_OK)
  {
    Error_Handler();
  }

  /** Configure the ADC multi-mode
  */
  multimode.Mode = ADC_MODE_INDEPENDENT;
  if (HAL_ADCEx_MultiModeConfigChannel(&hadc3, &multimode) != HAL_OK)
  {
    Error_Handler();
  }

  /** Configure Regular Channel
  */
  sConfig.Channel = ADC_CHANNEL_5;
  sConfig.Rank = ADC_REGULAR_RANK_1;
  sConfig.SamplingTime = ADC_SAMPLETIME_47CYCLES_5;
  sConfig.SingleDiff = ADC_SINGLE_ENDED;
  sConfig.OffsetNumber = ADC_OFFSET_NONE;
  sConfig.Offset = 0;
  if (HAL_ADC_ConfigChannel(&hadc3, &sConfig) != HAL_OK)
  {
    Error_Handler();
  }

}

static void MX_ADC4_Init(void)
{

  ADC_ChannelConfTypeDef sConfig = {0};

  /** Common config
  */
  hadc4.Instance = ADC4;
  hadc4.Init.ClockPrescaler = ADC_CLOCK_SYNC_PCLK_DIV4;
  hadc4.Init.Resolution = ADC_RESOLUTION_12B;
  hadc4.Init.DataAlign = ADC_DATAALIGN_RIGHT;
  hadc4.Init.GainCompensation = 0;
  hadc4.Init.ScanConvMode = ADC_SCAN_DISABLE;
  hadc4.Init.EOCSelection = ADC_EOC_SINGLE_CONV;
  hadc4.Init.LowPowerAutoWait = DISABLE;
  hadc4.Init.ContinuousConvMode = ENABLE;
  hadc4.Init.NbrOfConversion = 1;
  hadc4.Init.DiscontinuousConvMode = DISABLE;
  hadc4.Init.ExternalTrigConv = ADC_SOFTWARE_START;
  hadc4.Init.ExternalTrigConvEdge = ADC_EXTERNALTRIGCONVEDGE_NONE;
  hadc4.Init.DMAContinuousRequests = ENABLE;
  hadc4.Init.Overrun = ADC_OVR_DATA_PRESERVED;
  hadc4.Init.OversamplingMode = ENABLE;
  hadc4.Init.Oversampling.Ratio = ADC_OVERSAMPLING_RATIO_128;
  hadc4.Init.Oversampling.RightBitShift = ADC_RIGHTBITSHIFT_7;
  hadc4.Init.Oversampling.TriggeredMode = ADC_TRIGGEREDMODE_SINGLE_TRIGGER;
  hadc4.Init.Oversampling.OversamplingStopReset = ADC_REGOVERSAMPLING_CONTINUED_MODE;
  if (HAL_ADC_Init(&hadc4) != HAL_OK)
  {
    Error_Handler();
  }

  /** Configure Regular Channel
  */
  sConfig.Channel = ADC_CHANNEL_5;
  sConfig.Rank = ADC_REGULAR_RANK_1;
  sConfig.SamplingTime = ADC_SAMPLETIME_2CYCLES_5;
  sConfig.SingleDiff = ADC_SINGLE_ENDED;
  sConfig.OffsetNumber = ADC_OFFSET_NONE;
  sConfig.Offset = 0;
  if (HAL_ADC_ConfigChannel(&hadc4, &sConfig) != HAL_OK)
  {
    Error_Handler();
  }

}

static void MX_ADC5_Init(void)
{

  ADC_ChannelConfTypeDef sConfig = {0};

  /** Common config
  */
  hadc5.Instance = ADC5;
  hadc5.Init.ClockPrescaler = ADC_CLOCK_SYNC_PCLK_DIV4;
  hadc5.Init.Resolution = ADC_RESOLUTION_12B;
  hadc5.Init.DataAlign = ADC_DATAALIGN_RIGHT;
  hadc5.Init.GainCompensation = 0;
  hadc5.Init.ScanConvMode = ADC_SCAN_DISABLE;
  hadc5.Init.EOCSelection = ADC_EOC_SEQ_CONV;
  hadc5.Init.LowPowerAutoWait = DISABLE;
  hadc5.Init.ContinuousConvMode = ENABLE;
  hadc5.Init.NbrOfConversion = 1;
  hadc5.Init.DiscontinuousConvMode = DISABLE;
  hadc5.Init.ExternalTrigConv = ADC_SOFTWARE_START;
  hadc5.Init.ExternalTrigConvEdge = ADC_EXTERNALTRIGCONVEDGE_NONE;
  hadc5.Init.DMAContinuousRequests = ENABLE;
  hadc5.Init.Overrun = ADC_OVR_DATA_PRESERVED;
  hadc5.Init.OversamplingMode = ENABLE;
  hadc5.Init.Oversampling.Ratio = ADC_OVERSAMPLING_RATIO_128;
  hadc5.Init.Oversampling.RightBitShift = ADC_RIGHTBITSHIFT_7;
  hadc5.Init.Oversampling.TriggeredMode = ADC_TRIGGEREDMODE_SINGLE_TRIGGER;
  hadc5.Init.Oversampling.OversamplingStopReset = ADC_REGOVERSAMPLING_CONTINUED_MODE;
  if (HAL_ADC_Init(&hadc5) != HAL_OK)
  {
    Error_Handler();
  }

  /** Configure Regular Channel
  */
  sConfig.Channel = ADC_CHANNEL_2;
  sConfig.Rank = ADC_REGULAR_RANK_1;
  sConfig.SamplingTime = ADC_SAMPLETIME_47CYCLES_5;
  sConfig.SingleDiff = ADC_SINGLE_ENDED;
  sConfig.OffsetNumber = ADC_OFFSET_NONE;
  sConfig.Offset = 0;
  if (HAL_ADC_ConfigChannel(&hadc5, &sConfig) != HAL_OK)
  {
    Error_Handler();
  }

}

static void MX_I2C2_Init(void)
{

  hi2c2.Instance = I2C2;
  hi2c2.Init.Timing = 0x30A0A7FB;
  hi2c2.Init.OwnAddress1 = 0;
  hi2c2.Init.AddressingMode = I2C_ADDRESSINGMODE_7BIT;
  hi2c2.Init.DualAddressMode = I2C_DUALADDRESS_DISABLE;
  hi2c2.Init.OwnAddress2 = 0;
  hi2c2.Init.OwnAddress2Masks = I2C_OA2_NOMASK;
  hi2c2.Init.GeneralCallMode = I2C_GENERALCALL_DISABLE;
  hi2c2.Init.NoStretchMode = I2C_NOSTRETCH_DISABLE;
  if (HAL_I2C_Init(&hi2c2) != HAL_OK)
  {
    Error_Handler();
  }

  /** Configure Analogue filter
  */
  if (HAL_I2CEx_ConfigAnalogFilter(&hi2c2, I2C_ANALOGFILTER_ENABLE) != HAL_OK)
  {
    Error_Handler();
  }

  /** Configure Digital filter
  */
  if (HAL_I2CEx_ConfigDigitalFilter(&hi2c2, 0) != HAL_OK)
  {
    Error_Handler();
  }

}

static void MX_LPUART1_UART_Init(void)
{

  hlpuart1.Instance = LPUART1;
  hlpuart1.Init.BaudRate = 115200;
  hlpuart1.Init.WordLength = UART_WORDLENGTH_8B;
  hlpuart1.Init.StopBits = UART_STOPBITS_1;
  hlpuart1.Init.Parity = UART_PARITY_NONE;
  hlpuart1.Init.Mode = UART_MODE_TX_RX;
  hlpuart1.Init.HwFlowCtl = UART_HWCONTROL_NONE;
  hlpuart1.Init.OneBitSampling = UART_ONE_BIT_SAMPLE_DISABLE;
  hlpuart1.Init.ClockPrescaler = UART_PRESCALER_DIV1;
  hlpuart1.AdvancedInit.AdvFeatureInit = UART_ADVFEATURE_NO_INIT;
  if (HAL_UART_Init(&hlpuart1) != HAL_OK)
  {
    Error_Handler();
  }
  if (HAL_UARTEx_SetTxFifoThreshold(&hlpuart1, UART_TXFIFO_THRESHOLD_1_8) != HAL_OK)
  {
    Error_Handler();
  }
  if (HAL_UARTEx_SetRxFifoThreshold(&hlpuart1, UART_RXFIFO_THRESHOLD_1_8) != HAL_OK)
  {
    Error_Handler();
  }
  if (HAL_UARTEx_DisableFifoMode(&hlpuart1) != HAL_OK)
  {
    Error_Handler();
  }

}

static void MX_USART3_UART_Init(void)
{

  huart3.Instance = USART3;
  huart3.Init.BaudRate = 115200;
  huart3.Init.WordLength = UART_WORDLENGTH_8B;
  huart3.Init.StopBits = UART_STOPBITS_1;
  huart3.Init.Parity = UART_PARITY_NONE;
  huart3.Init.Mode = UART_MODE_TX_RX;
  huart3.Init.HwFlowCtl = UART_HWCONTROL_NONE;
  huart3.Init.OverSampling = UART_OVERSAMPLING_16;
  huart3.Init.OneBitSampling = UART_ONE_BIT_SAMPLE_DISABLE;
  huart3.Init.ClockPrescaler = UART_PRESCALER_DIV1;
  huart3.AdvancedInit.AdvFeatureInit = UART_ADVFEATURE_NO_INIT;
  if (HAL_UART_Init(&huart3) != HAL_OK)
  {
    Error_Handler();
  }
  if (HAL_UARTEx_SetTxFifoThreshold(&huart3, UART_TXFIFO_THRESHOLD_1_8) != HAL_OK)
  {
    Error_Handler();
  }
  if (HAL_UARTEx_SetRxFifoThreshold(&huart3, UART_RXFIFO_THRESHOLD_1_8) != HAL_OK)
  {
    Error_Handler();
  }
  if (HAL_UARTEx_DisableFifoMode(&huart3) != HAL_OK)
  {
    Error_Handler();
  }

}

static void MX_OPAMP1_Init(void)
{

  hopamp1.Instance = OPAMP1;
  hopamp1.Init.PowerMode = OPAMP_POWERMODE_NORMALSPEED;
  hopamp1.Init.Mode = OPAMP_PGA_MODE;
  hopamp1.Init.NonInvertingInput = OPAMP_NONINVERTINGINPUT_IO2;
  hopamp1.Init.InternalOutput = ENABLE;
  hopamp1.Init.TimerControlledMuxmode = OPAMP_TIMERCONTROLLEDMUXMODE_DISABLE;
  hopamp1.Init.PgaConnect = OPAMP_PGA_CONNECT_INVERTINGINPUT_NO;
  hopamp1.Init.PgaGain = OPAMP_PGA_GAIN_2_OR_MINUS_1;
  hopamp1.Init.UserTrimming = OPAMP_TRIMMING_FACTORY;
  if (HAL_OPAMP_Init(&hopamp1) != HAL_OK)
  {
    Error_Handler();
  }

}

static void MX_OPAMP2_Init(void)
{

  hopamp2.Instance = OPAMP2;
  hopamp2.Init.PowerMode = OPAMP_POWERMODE_NORMALSPEED;
  hopamp2.Init.Mode = OPAMP_PGA_MODE;
  hopamp2.Init.NonInvertingInput = OPAMP_NONINVERTINGINPUT_IO0;
  hopamp2.Init.InternalOutput = ENABLE;
  hopamp2.Init.TimerControlledMuxmode = OPAMP_TIMERCONTROLLEDMUXMODE_DISABLE;
  hopamp2.Init.PgaConnect = OPAMP_PGA_CONNECT_INVERTINGINPUT_NO;
  hopamp2.Init.PgaGain = OPAMP_PGA_GAIN_2_OR_MINUS_1;
  hopamp2.Init.UserTrimming = OPAMP_TRIMMING_FACTORY;
  if (HAL_OPAMP_Init(&hopamp2) != HAL_OK)
  {
    Error_Handler();
  }

}

static void MX_TIM1_Init(void)
{

  TIM_ClockConfigTypeDef sClockSourceConfig = {0};
  TIM_MasterConfigTypeDef sMasterConfig = {0};
  TIM_OC_InitTypeDef sConfigOC = {0};
  TIM_BreakDeadTimeConfigTypeDef sBreakDeadTimeConfig = {0};

  htim1.Instance = TIM1;
  htim1.Init.Prescaler = 170-1;
  htim1.Init.CounterMode = TIM_COUNTERMODE_UP;
  htim1.Init.Period = 99;
  htim1.Init.ClockDivision = TIM_CLOCKDIVISION_DIV1;
  htim1.Init.RepetitionCounter = 0;
  htim1.Init.AutoReloadPreload = TIM_AUTORELOAD_PRELOAD_DISABLE;
  if (HAL_TIM_Base_Init(&htim1) != HAL_OK)
  {
    Error_Handler();
  }
  sClockSourceConfig.ClockSource = TIM_CLOCKSOURCE_INTERNAL;
  if (HAL_TIM_ConfigClockSource(&htim1, &sClockSourceConfig) != HAL_OK)
  {
    Error_Handler();
  }
  if (HAL_TIM_PWM_Init(&htim1) != HAL_OK)
  {
    Error_Handler();
  }
  sMasterConfig.MasterOutputTrigger = TIM_TRGO_RESET;
  sMasterConfig.MasterOutputTrigger2 = TIM_TRGO2_RESET;
  sMasterConfig.MasterSlaveMode = TIM_MASTERSLAVEMODE_DISABLE;
  if (HAL_TIMEx_MasterConfigSynchronization(&htim1, &sMasterConfig) != HAL_OK)
  {
    Error_Handler();
  }
  sConfigOC.OCMode = TIM_OCMODE_PWM1;
  sConfigOC.Pulse = 0;
  sConfigOC.OCPolarity = TIM_OCPOLARITY_HIGH;
  sConfigOC.OCNPolarity = TIM_OCNPOLARITY_HIGH;
  sConfigOC.OCFastMode = TIM_OCFAST_DISABLE;
  sConfigOC.OCIdleState = TIM_OCIDLESTATE_RESET;
  sConfigOC.OCNIdleState = TIM_OCNIDLESTATE_RESET;
  if (HAL_TIM_PWM_ConfigChannel(&htim1, &sConfigOC, TIM_CHANNEL_1) != HAL_OK)
  {
    Error_Handler();
  }
  if (HAL_TIM_PWM_ConfigChannel(&htim1, &sConfigOC, TIM_CHANNEL_2) != HAL_OK)
  {
    Error_Handler();
  }
  sBreakDeadTimeConfig.OffStateRunMode = TIM_OSSR_DISABLE;
  sBreakDeadTimeConfig.OffStateIDLEMode = TIM_OSSI_DISABLE;
  sBreakDeadTimeConfig.LockLevel = TIM_LOCKLEVEL_OFF;
  sBreakDeadTimeConfig.DeadTime = 0;
  sBreakDeadTimeConfig.BreakState = TIM_BREAK_DISABLE;
  sBreakDeadTimeConfig.BreakPolarity = TIM_BREAKPOLARITY_HIGH;
  sBreakDeadTimeConfig.BreakFilter = 0;
  sBreakDeadTimeConfig.BreakAFMode = TIM_BREAK_AFMODE_INPUT;
  sBreakDeadTimeConfig.Break2State = TIM_BREAK2_DISABLE;
  sBreakDeadTimeConfig.Break2Polarity = TIM_BREAK2POLARITY_HIGH;
  sBreakDeadTimeConfig.Break2Filter = 0;
  sBreakDeadTimeConfig.Break2AFMode = TIM_BREAK_AFMODE_INPUT;
  sBreakDeadTimeConfig.AutomaticOutput = TIM_AUTOMATICOUTPUT_DISABLE;
  if (HAL_TIMEx_ConfigBreakDeadTime(&htim1, &sBreakDeadTimeConfig) != HAL_OK)
  {
    Error_Handler();
  }
  HAL_TIM_MspPostInit(&htim1);

}

static void MX_TIM2_Init(void)
{

  TIM_ClockConfigTypeDef sClockSourceConfig = {0};
  TIM_MasterConfigTypeDef sMasterConfig = {0};

  htim2.Instance = TIM2;
  htim2.Init.Prescaler = 0;
  htim2.Init.CounterMode = TIM_COUNTERMODE_UP;
  htim2.Init.Period = 4.294967295E9;
  htim2.Init.ClockDivision = TIM_CLOCKDIVISION_DIV1;
  htim2.Init.AutoReloadPreload = TIM_AUTORELOAD_PRELOAD_DISABLE;
  if (HAL_TIM_Base_Init(&htim2) != HAL_OK)
  {
    Error_Handler();
  }
  sClockSourceConfig.ClockSource = TIM_CLOCKSOURCE_INTERNAL;
  if (HAL_TIM_ConfigClockSource(&htim2, &sClockSourceConfig) != HAL_OK)
  {
    Error_Handler();
  }
  sMasterConfig.MasterOutputTrigger = TIM_TRGO_RESET;
  sMasterConfig.MasterSlaveMode = TIM_MASTERSLAVEMODE_DISABLE;
  if (HAL_TIMEx_MasterConfigSynchronization(&htim2, &sMasterConfig) != HAL_OK)
  {
    Error_Handler();
  }

}

static void MX_TIM3_Init(void)
{

  TIM_ClockConfigTypeDef sClockSourceConfig = {0};
  TIM_MasterConfigTypeDef sMasterConfig = {0};
  TIM_IC_InitTypeDef sConfigIC = {0};

  htim3.Instance = TIM3;
  htim3.Init.Prescaler = 170-1;
  htim3.Init.CounterMode = TIM_COUNTERMODE_UP;
  htim3.Init.Period = 99;
  htim3.Init.ClockDivision = TIM_CLOCKDIVISION_DIV1;
  htim3.Init.AutoReloadPreload = TIM_AUTORELOAD_PRELOAD_DISABLE;
  if (HAL_TIM_Base_Init(&htim3) != HAL_OK)
  {
    Error_Handler();
  }
  sClockSourceConfig.ClockSource = TIM_CLOCKSOURCE_INTERNAL;
  if (HAL_TIM_ConfigClockSource(&htim3, &sClockSourceConfig) != HAL_OK)
  {
    Error_Handler();
  }
  if (HAL_TIM_IC_Init(&htim3) != HAL_OK)
  {
    Error_Handler();
  }
  sMasterConfig.MasterOutputTrigger = TIM_TRGO_RESET;
  sMasterConfig.MasterSlaveMode = TIM_MASTERSLAVEMODE_DISABLE;
  if (HAL_TIMEx_MasterConfigSynchronization(&htim3, &sMasterConfig) != HAL_OK)
  {
    Error_Handler();
  }
  sConfigIC.ICPolarity = TIM_INPUTCHANNELPOLARITY_RISING;
  sConfigIC.ICSelection = TIM_ICSELECTION_DIRECTTI;
  sConfigIC.ICPrescaler = TIM_ICPSC_DIV1;
  sConfigIC.ICFilter = 0;
  if (HAL_TIM_IC_ConfigChannel(&htim3, &sConfigIC, TIM_CHANNEL_2) != HAL_OK)
  {
    Error_Handler();
  }

}

static void MX_TIM8_Init(void)
{

  TIM_ClockConfigTypeDef sClockSourceConfig = {0};
  TIM_MasterConfigTypeDef sMasterConfig = {0};
  TIM_OC_InitTypeDef sConfigOC = {0};
  TIM_BreakDeadTimeConfigTypeDef sBreakDeadTimeConfig = {0};

  htim8.Instance = TIM8;
  htim8.Init.Prescaler = 170-1;
  htim8.Init.CounterMode = TIM_COUNTERMODE_UP;
  htim8.Init.Period = 999;
  htim8.Init.ClockDivision = TIM_CLOCKDIVISION_DIV1;
  htim8.Init.RepetitionCounter = 0;
  htim8.Init.AutoReloadPreload = TIM_AUTORELOAD_PRELOAD_DISABLE;
  if (HAL_TIM_Base_Init(&htim8) != HAL_OK)
  {
    Error_Handler();
  }
  sClockSourceConfig.ClockSource = TIM_CLOCKSOURCE_INTERNAL;
  if (HAL_TIM_ConfigClockSource(&htim8, &sClockSourceConfig) != HAL_OK)
  {
    Error_Handler();
  }
  if (HAL_TIM_PWM_Init(&htim8) != HAL_OK)
  {
    Error_Handler();
  }
  sMasterConfig.MasterOutputTrigger = TIM_TRGO_RESET;
  sMasterConfig.MasterOutputTrigger2 = TIM_TRGO2_RESET;
  sMasterConfig.MasterSlaveMode = TIM_MASTERSLAVEMODE_DISABLE;
  if (HAL_TIMEx_MasterConfigSynchronization(&htim8, &sMasterConfig) != HAL_OK)
  {
    Error_Handler();
  }
  sConfigOC.OCMode = TIM_OCMODE_PWM1;
  sConfigOC.Pulse = 0;
  sConfigOC.OCPolarity = TIM_OCPOLARITY_HIGH;
  sConfigOC.OCNPolarity = TIM_OCNPOLARITY_HIGH;
  sConfigOC.OCFastMode = TIM_OCFAST_DISABLE;
  sConfigOC.OCIdleState = TIM_OCIDLESTATE_RESET;
  sConfigOC.OCNIdleState = TIM_OCNIDLESTATE_RESET;
  if (HAL_TIM_PWM_ConfigChannel(&htim8, &sConfigOC, TIM_CHANNEL_1) != HAL_OK)
  {
    Error_Handler();
  }
  sBreakDeadTimeConfig.OffStateRunMode = TIM_OSSR_DISABLE;
  sBreakDeadTimeConfig.OffStateIDLEMode = TIM_OSSI_DISABLE;
  sBreakDeadTimeConfig.LockLevel = TIM_LOCKLEVEL_OFF;
  sBreakDeadTimeConfig.DeadTime = 0;
  sBreakDeadTimeConfig.BreakState = TIM_BREAK_DISABLE;
  sBreakDeadTimeConfig.BreakPolarity = TIM_BREAKPOLARITY_HIGH;
  sBreakDeadTimeConfig.BreakFilter = 0;
  sBreakDeadTimeConfig.BreakAFMode = TIM_BREAK_AFMODE_INPUT;
  sBreakDeadTimeConfig.Break2State = TIM_BREAK2_DISABLE;
  sBreakDeadTimeConfig.Break2Polarity = TIM_BREAK2POLARITY_HIGH;
  sBreakDeadTimeConfig.Break2Filter = 0;
  sBreakDeadTimeConfig.Break2AFMode = TIM_BREAK_AFMODE_INPUT;
  sBreakDeadTimeConfig.AutomaticOutput = TIM_AUTOMATICOUTPUT_DISABLE;
  if (HAL_TIMEx_ConfigBreakDeadTime(&htim8, &sBreakDeadTimeConfig) != HAL_OK)
  {
    Error_Handler();
  }
  HAL_TIM_MspPostInit(&htim8);

}

static void MX_TIM16_Init(void)
{

  TIM_IC_InitTypeDef sConfigIC = {0};

  htim16.Instance = TIM16;
  htim16.Init.Prescaler = 0;
  htim16.Init.CounterMode = TIM_COUNTERMODE_UP;
  htim16.Init.Period = 65535;
  htim16.Init.ClockDivision = TIM_CLOCKDIVISION_DIV1;
  htim16.Init.RepetitionCounter = 0;
  htim16.Init.AutoReloadPreload = TIM_AUTORELOAD_PRELOAD_DISABLE;
  if (HAL_TIM_Base_Init(&htim16) != HAL_OK)
  {
    Error_Handler();
  }
  if (HAL_TIM_IC_Init(&htim16) != HAL_OK)
  {
    Error_Handler();
  }
  sConfigIC.ICPolarity = TIM_INPUTCHANNELPOLARITY_RISING;
  sConfigIC.ICSelection = TIM_ICSELECTION_DIRECTTI;
  sConfigIC.ICPrescaler = TIM_ICPSC_DIV1;
  sConfigIC.ICFilter = 0;
  if (HAL_TIM_IC_ConfigChannel(&htim16, &sConfigIC, TIM_CHANNEL_1) != HAL_OK)
  {
    Error_Handler();
  }

}

static void MX_TIM17_Init(void)
{

  TIM_IC_InitTypeDef sConfigIC = {0};

  htim17.Instance = TIM17;
  htim17.Init.Prescaler = 0;
  htim17.Init.CounterMode = TIM_COUNTERMODE_UP;
  htim17.Init.Period = 65535;
  htim17.Init.ClockDivision = TIM_CLOCKDIVISION_DIV1;
  htim17.Init.RepetitionCounter = 0;
  htim17.Init.AutoReloadPreload = TIM_AUTORELOAD_PRELOAD_DISABLE;
  if (HAL_TIM_Base_Init(&htim17) != HAL_OK)
  {
    Error_Handler();
  }
  if (HAL_TIM_IC_Init(&htim17) != HAL_OK)
  {
    Error_Handler();
  }
  sConfigIC.ICPolarity = TIM_INPUTCHANNELPOLARITY_RISING;
  sConfigIC.ICSelection = TIM_ICSELECTION_DIRECTTI;
  sConfigIC.ICPrescaler = TIM_ICPSC_DIV1;
  sConfigIC.ICFilter = 0;
  if (HAL_TIM_IC_ConfigChannel(&htim17, &sConfigIC, TIM_CHANNEL_1) != HAL_OK)
  {
    Error_Handler();
  }

}

static void MX_TIM20_Init(void)
{

  TIM_ClockConfigTypeDef sClockSourceConfig = {0};
  TIM_MasterConfigTypeDef sMasterConfig = {0};
  TIM_OC_InitTypeDef sConfigOC = {0};
  TIM_BreakDeadTimeConfigTypeDef sBreakDeadTimeConfig = {0};

  htim20.Instance = TIM20;
  htim20.Init.Prescaler = 0;
  htim20.Init.CounterMode = TIM_COUNTERMODE_UP;
  htim20.Init.Period = 65535;
  htim20.Init.ClockDivision = TIM_CLOCKDIVISION_DIV1;
  htim20.Init.RepetitionCounter = 0;
  htim20.Init.AutoReloadPreload = TIM_AUTORELOAD_PRELOAD_DISABLE;
  if (HAL_TIM_Base_Init(&htim20) != HAL_OK)
  {
    Error_Handler();
  }
  sClockSourceConfig.ClockSource = TIM_CLOCKSOURCE_INTERNAL;
  if (HAL_TIM_ConfigClockSource(&htim20, &sClockSourceConfig) != HAL_OK)
  {
    Error_Handler();
  }
  if (HAL_TIM_OC_Init(&htim20) != HAL_OK)
  {
    Error_Handler();
  }
  sMasterConfig.MasterOutputTrigger = TIM_TRGO_RESET;
  sMasterConfig.MasterOutputTrigger2 = TIM_TRGO2_RESET;
  sMasterConfig.MasterSlaveMode = TIM_MASTERSLAVEMODE_DISABLE;
  if (HAL_TIMEx_MasterConfigSynchronization(&htim20, &sMasterConfig) != HAL_OK)
  {
    Error_Handler();
  }
  sConfigOC.OCMode = TIM_OCMODE_TIMING;
  sConfigOC.Pulse = 0;
  sConfigOC.OCPolarity = TIM_OCPOLARITY_HIGH;
  sConfigOC.OCNPolarity = TIM_OCNPOLARITY_HIGH;
  sConfigOC.OCFastMode = TIM_OCFAST_DISABLE;
  sConfigOC.OCIdleState = TIM_OCIDLESTATE_RESET;
  sConfigOC.OCNIdleState = TIM_OCNIDLESTATE_RESET;
  if (HAL_TIM_OC_ConfigChannel(&htim20, &sConfigOC, TIM_CHANNEL_1) != HAL_OK)
  {
    Error_Handler();
  }
  sBreakDeadTimeConfig.OffStateRunMode = TIM_OSSR_DISABLE;
  sBreakDeadTimeConfig.OffStateIDLEMode = TIM_OSSI_DISABLE;
  sBreakDeadTimeConfig.LockLevel = TIM_LOCKLEVEL_OFF;
  sBreakDeadTimeConfig.DeadTime = 0;
  sBreakDeadTimeConfig.BreakState = TIM_BREAK_DISABLE;
  sBreakDeadTimeConfig.BreakPolarity = TIM_BREAKPOLARITY_HIGH;
  sBreakDeadTimeConfig.BreakFilter = 0;
  sBreakDeadTimeConfig.BreakAFMode = TIM_BREAK_AFMODE_INPUT;
  sBreakDeadTimeConfig.Break2State = TIM_BREAK2_DISABLE;
  sBreakDeadTimeConfig.Break2Polarity = TIM_BREAK2POLARITY_HIGH;
  sBreakDeadTimeConfig.Break2Filter = 0;
  sBreakDeadTimeConfig.Break2AFMode = TIM_BREAK_AFMODE_INPUT;
  sBreakDeadTimeConfig.AutomaticOutput = TIM_AUTOMATICOUTPUT_DISABLE;
  if (HAL_TIMEx_ConfigBreakDeadTime(&htim20, &sBreakDeadTimeConfig) != HAL_OK)
  {
    Error_Handler();
  }
  HAL_TIM_MspPostInit(&htim20);

}

static void MX_DMA_Init(void)
{

  /* DMA controller clock enable */
  __HAL_RCC_DMAMUX1_CLK_ENABLE();
  __HAL_RCC_DMA1_CLK_ENABLE();
  __HAL_RCC_DMA2_CLK_ENABLE();

  /* DMA interrupt init */
  /* DMA1_Channel1_IRQn interrupt configuration */
  HAL_NVIC_SetPriority(DMA1_Channel1_IRQn, 5, 0);
  HAL_NVIC_EnableIRQ(DMA1_Channel1_IRQn);
  /* DMA1_Channel2_IRQn interrupt configuration */
  HAL_NVIC_SetPriority(DMA1_Channel2_IRQn, 5, 0);
  HAL_NVIC_EnableIRQ(DMA1_Channel2_IRQn);
  /* DMA1_Channel3_IRQn interrupt configuration */
  HAL_NVIC_SetPriority(DMA1_Channel3_IRQn, 5, 0);
  HAL_NVIC_EnableIRQ(DMA1_Channel3_IRQn);
  /* DMA1_Channel4_IRQn interrupt configuration */
  HAL_NVIC_SetPriority(DMA1_Channel4_IRQn, 5, 0);
  HAL_NVIC_EnableIRQ(DMA1_Channel4_IRQn);
  /* DMA1_Channel5_IRQn interrupt configuration */
  HAL_NVIC_SetPriority(DMA1_Channel5_IRQn, 5, 0);
  HAL_NVIC_EnableIRQ(DMA1_Channel5_IRQn);
  /* DMA2_Channel6_IRQn interrupt configuration */
  HAL_NVIC_SetPriority(DMA2_Channel6_IRQn, 5, 0);
  HAL_NVIC_EnableIRQ(DMA2_Channel6_IRQn);
  /* DMA2_Channel7_IRQn interrupt configuration */
  HAL_NVIC_SetPriority(DMA2_Channel7_IRQn, 5, 0);
  HAL_NVIC_EnableIRQ(DMA2_Channel7_IRQn);

}

static void MX_GPIO_Init(void)
{
  GPIO_InitTypeDef GPIO_InitStruct = {0};

  /* GPIO Ports Clock Enable */
  __HAL_RCC_GPIOC_CLK_ENABLE();
  __HAL_RCC_GPIOF_CLK_ENABLE();
  __HAL_RCC_GPIOA_CLK_ENABLE();
  __HAL_RCC_GPIOB_CLK_ENABLE();
  __HAL_RCC_GPIOD_CLK_ENABLE();

  /*Configure GPIO pin Output Level */
  HAL_GPIO_WritePin(GPIOA, LED_Y_Pin|Motor_Esq_IN4_Pin|LED_R_PWM_Pin|LED_G_PWM_Pin, GPIO_PIN_RESET);

  /*Configure GPIO pin Output Level */
  HAL_GPIO_WritePin(GPIOB, Motor_Dir_IN1_Pin|Motor_Esq_IN3_Pin|LED_B_PWM_Pin|Motor_Dir_IN2_Pin, GPIO_PIN_RESET);

  /*Configure GPIO pin : B1_Pin */
  GPIO_InitStruct.Pin = B1_Pin;
  GPIO_InitStruct.Mode = GPIO_MODE_IT_RISING;
  GPIO_InitStruct.Pull = GPIO_NOPULL;
  HAL_GPIO_Init(B1_GPIO_Port, &GPIO_InitStruct);

  /*Configure GPIO pins : LED_Y_Pin Motor_Esq_IN4_Pin LED_R_PWM_Pin LED_G_PWM_Pin */
  GPIO_InitStruct.Pin = LED_Y_Pin|Motor_Esq_IN4_Pin|LED_R_PWM_Pin|LED_G_PWM_Pin;
  GPIO_InitStruct.Mode = GPIO_MODE_OUTPUT_PP;
  GPIO_InitStruct.Pull = GPIO_NOPULL;
  GPIO_InitStruct.Speed = GPIO_SPEED_FREQ_LOW;
  HAL_GPIO_Init(GPIOA, &GPIO_InitStruct);

  /*Configure GPIO pin : BT_Enter_Pin */
  GPIO_InitStruct.Pin = BT_Enter_Pin;
  GPIO_InitStruct.Mode = GPIO_MODE_INPUT;
  GPIO_InitStruct.Pull = GPIO_PULLUP;
  HAL_GPIO_Init(BT_Enter_GPIO_Port, &GPIO_InitStruct);

  /*Configure GPIO pins : Motor_Dir_IN1_Pin Motor_Esq_IN3_Pin LED_B_PWM_Pin Motor_Dir_IN2_Pin */
  GPIO_InitStruct.Pin = Motor_Dir_IN1_Pin|Motor_Esq_IN3_Pin|LED_B_PWM_Pin|Motor_Dir_IN2_Pin;
  GPIO_InitStruct.Mode = GPIO_MODE_OUTPUT_PP;
  GPIO_InitStruct.Pull = GPIO_NOPULL;
  GPIO_InitStruct.Speed = GPIO_SPEED_FREQ_LOW;
  HAL_GPIO_Init(GPIOB, &GPIO_InitStruct);

  /*Configure GPIO pins : BT_Baixo_Pin BT_Esq_Pin BT_Dir_Pin */
  GPIO_InitStruct.Pin = BT_Baixo_Pin|BT_Esq_Pin|BT_Dir_Pin;
  GPIO_InitStruct.Mode = GPIO_MODE_INPUT;
  GPIO_InitStruct.Pull = GPIO_NOPULL;
  HAL_GPIO_Init(GPIOC, &GPIO_InitStruct);

  /*Configure GPIO pin : Switch_Fr_Pin */
  GPIO_InitStruct.Pin = Switch_Fr_Pin;
  GPIO_InitStruct.Mode = GPIO_MODE_IT_FALLING;
  GPIO_InitStruct.Pull = GPIO_PULLUP;
  HAL_GPIO_Init(Switch_Fr_GPIO_Port, &GPIO_InitStruct);

  /*Configure GPIO pin : BT_Cima_Pin */
  GPIO_InitStruct.Pin = BT_Cima_Pin;
  GPIO_InitStruct.Mode = GPIO_MODE_INPUT;
  GPIO_InitStruct.Pull = GPIO_NOPULL;
  HAL_GPIO_Init(BT_Cima_GPIO_Port, &GPIO_InitStruct);

  /* EXTI interrupt init*/
  HAL_NVIC_SetPriority(EXTI2_IRQn, 5, 0);
  HAL_NVIC_EnableIRQ(EXTI2_IRQn);

  HAL_NVIC_SetPriority(EXTI15_10_IRQn, 5, 0);
  HAL_NVIC_EnableIRQ(EXTI15_10_IRQn);

}

/* USER CODE BEGIN 4 */
void HAL_TIM_IC_CaptureCallback(TIM_HandleTypeDef *htim) {
    if (htim->Instance == TIM16) {
        vMotorEncoderHandleTimerCapture(MOTORENCODER_MOTOR_LEFT);
    } else if (htim->Instance == TIM17) {
        vMotorEncoderHandleTimerCapture(MOTORENCODER_MOTOR_RIGHT);
    }
}

/* USER CODE END 4 */

void task_Main(void *argument)
{
  for(;;)
  {
    osDelay(1);
  }
}

void HAL_TIM_PeriodElapsedCallback(TIM_HandleTypeDef *htim)
{
  /* USER CODE BEGIN Callback 0 */
	if (htim->Instance == TIM16) {
	    vMotorEncoderHandleTimerReset(MOTORENCODER_MOTOR_LEFT);
	} else if (htim->Instance == TIM17) {
	    vMotorEncoderHandleTimerReset(MOTORENCODER_MOTOR_RIGHT);
	}
  /* USER CODE END Callback 0 */
  if (htim->Instance == TIM6) {
    HAL_IncTick();
  }
}

void Error_Handler(void)
{
  __disable_irq();
  while (1)
  {
  }
}

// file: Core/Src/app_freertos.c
/* USER CODE BEGIN Header */
/**
  ******************************************************************************
  * File Name          : app_freertos.c
  * Description        : Code for freertos applications
  ******************************************************************************
  * @attention
  *
  * Copyright (c) 2026 STMicroelectronics.
  * All rights reserved.
  *
  * This software is licensed under terms that can be found in the LICENSE file
  * in the root directory of this software component.
  * If no LICENSE file comes with this software, it is provided AS-IS.
  *
  ******************************************************************************
  */
/* USER CODE END Header */

#include "FreeRTOS.h"
#include "task.h"
#include "main.h"

/* USER CODE BEGIN Includes */
#include "communicationStateMachine.h"
#include "lcd_hd44780_i2c.h"
#include "pid.h"
#include "motorEncoder.h"
#include "lineSensors_v2.h"
#include "battery.h"
#include <stdio.h>
#include "cmsis_os.h"
/* USER CODE END Includes */

/* USER CODE BEGIN Variables */
RoboData_t roboData;            // Variável global com os "sinais vitais" do robô
extern I2C_HandleTypeDef hi2c2; // Para podermos usar o Display no I2C2
extern TIM_HandleTypeDef htim1;
extern TIM_HandleTypeDef htim8;
extern TIM_HandleTypeDef htim16;
extern TIM_HandleTypeDef htim17;
extern osMutexId_t Mutex_SensoresHandle;
extern osMutexId_t Mutex_BatteryHandle;

pid_data_type xPidMotorDir;
pid_data_type xPidMotorEsq;

#define TRACK_WIDTH_CM  13.0f
#define V_BASE_CM_S     15.0f
uint8_t ucIniciado = 0U;

// --- VARI�?VEIS GLOBAIS DA BATERIA E ODOMETRIA ---
uint16_t gu16BateriaPorcentagem = 0U;
float gfVdirReal = 0.0f;
float gfVesqReal = 0.0f;
float gfDistanciaDireitaCM = 0.0f;
float gfDistanciaEsquerdaCM = 0.0f;

float fPosicaoLinha = 0.0f;   // �? posição da linha: -1.0 a +1.0
uint8_t ucSensoresIniciado = 0U;

/* USER CODE END Variables */

/* USER CODE BEGIN Application */

// Função chamada automaticamente pelo hardware (Interrupção) quando o Bumper é pressionado
void HAL_GPIO_EXTI_Callback(uint16_t GPIO_Pin) {
    if (GPIO_Pin == Switch_Fr_Pin) {
        // Acende o LED (RED) da placa para provar que a interrupção disparou!
        HAL_GPIO_WritePin(LED_R_PWM_GPIO_Port, LED_R_PWM_Pin, GPIO_PIN_SET);

        // TRAVA o robô em estado de emergência
        roboData.flag_colisao = 1;
    }
}

void task_Controle(void *argument) {
  static uint16_t contador_buzzer = 0;
  static uint8_t repeticao_buzzer = 0;

  for(;;) {
    // Leitura segura da flag de colisão usando o Mutex
    uint8_t estado_emergencia = 0;
    osMutexAcquire(Mutex_SensoresHandle, osWaitForever);
    estado_emergencia = roboData.flag_colisao;
    osMutexRelease(Mutex_SensoresHandle);

    // M�?QUINA DE ESTADOS: Verifica se o robô bateu
    if (estado_emergencia == 1) {
        // --- ESTADO DE EMERGÊNCIA (OBST�?CULO) ---

        // 1. Para os motores imediatamente (0% de Duty Cycle)
        __HAL_TIM_SET_COMPARE(&htim1, TIM_CHANNEL_1, 0);
        __HAL_TIM_SET_COMPARE(&htim1, TIM_CHANNEL_2, 0);

        // 2. Aciona o Buzzer por um tempo limitado a um numero de repetições (apita a cada ~250ms)
        if (repeticao_buzzer < 8) {
            contador_buzzer++;
            if (contador_buzzer < 25) { // 25 * 10ms = 250ms ligado
                __HAL_TIM_SET_COMPARE(&htim8, TIM_CHANNEL_1, 1000);
            } else if (contador_buzzer < 50) { // 250ms desligado
                __HAL_TIM_SET_COMPARE(&htim8, TIM_CHANNEL_1, 0);
            } else {
                contador_buzzer = 0; // Reinicia o ciclo
                repeticao_buzzer ++;
            }
        }
        osDelay(10);

    } else {
        repeticao_buzzer = 0;
        contador_buzzer = 0;
        __HAL_TIM_SET_COMPARE(&htim8, TIM_CHANNEL_1, 0);

        // Init único antes do loop
        if (ucIniciado == 0U) {
            vMotorEncoderInitMotors(
                Motor_Dir_IN1_GPIO_Port, Motor_Dir_IN1_Pin,
                Motor_Dir_IN2_GPIO_Port, Motor_Dir_IN2_Pin,
                Motor_Esq_IN3_GPIO_Port, Motor_Esq_IN3_Pin,
                Motor_Esq_IN4_GPIO_Port, Motor_Esq_IN4_Pin,
                &htim1, TIM_CHANNEL_2,   // PWM direito
                &htim1, TIM_CHANNEL_1    // PWM esquerdo
            );

            vMotorEncoderInitEncoders(
                &htim17, TIM_CHANNEL_1,  // encoder direito
                &htim16, TIM_CHANNEL_1   // encoder esquerdo
            );

            // PID motor direito: erro em cm/s → PWM [0.0, 1.0]
            vPidInit(&xPidMotorDir,  0.05f, 0.1f, 0.0f, 1.0f, 1.0f);
            // PID motor esquerdo
            vPidInit(&xPidMotorEsq,  0.05f, 0.1f, 0.0f, 1.0f, 1.0f);

            ucIniciado = 1U;
        }

        float fPosicao = 0.0f;
        osMutexAcquire(Mutex_SensoresHandle, osWaitForever);
        fPosicao = fPosicaoLinha;
        osMutexRelease(Mutex_SensoresHandle);

        // 2. Velocidade angular proporcional ao erro de posição
        float fOmega = 2.0f * fPosicao;  // rad/s

        // 3. Modelo cinemático diferencial → setpoints de velocidade
        float fVdirRef = V_BASE_CM_S + fOmega * (TRACK_WIDTH_CM / 2.0f);
        float fVesqRef = V_BASE_CM_S - fOmega * (TRACK_WIDTH_CM / 2.0f);

        // 4. Lê velocidades reais dos encoders (cm/s)
        float fVdirMed = fMotorEncoderReadVelocity(MOTORENCODER_MOTOR_RIGHT);
        float fVesqMed = fMotorEncoderReadVelocity(MOTORENCODER_MOTOR_LEFT);

        // 5. PIDs de velocidade → PWM [0.0, 1.0]
        float fPwmDir = fPidUpdateData(&xPidMotorDir, 2, fVdirMed);
        float fPwmEsq = fPidUpdateData(&xPidMotorEsq, 2, fVesqMed);

        // 6. Aplica nos motores
        vMotorEncoderControlMotor(MOTORENCODER_MOTOR_RIGHT,
            MOTORENCODER_DIRECTION_BACKWARD, fPwmDir);
        vMotorEncoderControlMotor(MOTORENCODER_MOTOR_LEFT,
            MOTORENCODER_DIRECTION_FORWARD, fPwmEsq);
        osDelay(30);
    }
  }
}

void task_Sensores(void *argument) {
  for(;;) {
    // Verifica se o botão Enter (PC5) foi pressionado (Pressionado = RESET)
    if (HAL_GPIO_ReadPin(BT_Enter_GPIO_Port, BT_Enter_Pin) == GPIO_PIN_RESET) {
        osDelay(30); // Debounce simples

        if (HAL_GPIO_ReadPin(BT_Enter_GPIO_Port, BT_Enter_Pin) == GPIO_PIN_RESET) {
            // Acesso protegido para alterar a flag
            osMutexAcquire(Mutex_SensoresHandle, osWaitForever);
            if (roboData.flag_colisao == 1) {
                roboData.flag_colisao = 0; // Limpa a flag (Destrava o robô)

                // Apaga o LED Vermelho de indicação de falha
                HAL_GPIO_WritePin(LED_R_PWM_GPIO_Port, LED_R_PWM_Pin, GPIO_PIN_RESET);
            }
            osMutexRelease(Mutex_SensoresHandle);

            // Aguarda o botão ser solto
            while (HAL_GPIO_ReadPin(BT_Enter_GPIO_Port, BT_Enter_Pin) == GPIO_PIN_RESET) {
                osDelay(10);
            }
        }
    }
    osDelay(20); // Executa a 50Hz
  }
}

void task_Bluetooth(void *argument) {
  /* Loop infinito da task de Bluetooth */
  for(;;) {
    osDelay(100); // Atraso de 100ms (10Hz)
  }
}

void task_Odometria(void *argument) {
  const float fDeltaT = 0.05f;

  // Fator de suavização (Alfa): quanto menor, mais estável fica o valor,
  // mas demora um pouquinho mais para subir. 0.3f é o equilíbrio perfeito.
  const float fAlfa = 0.3f;

  for(;;) {
    // 1. Coleta a velocidade instantânea bruta da biblioteca
    float fVdirBruta = fMotorEncoderReadVelocity(MOTORENCODER_MOTOR_RIGHT);
    float fVesqBruta = fMotorEncoderReadVelocity(MOTORENCODER_MOTOR_LEFT);

    // 2. Filtro de pulo (Ignora zeros falsos da biblioteca)
    if (fVdirBruta == 0.0f && gfVdirReal > 2.0f) fVdirBruta = gfVdirReal;
    if (fVesqBruta == 0.0f && gfVesqReal > 2.0f) fVesqBruta = gfVesqReal;

    // 3. FILTRO DIGITAL PASSA-BAIXAS (Suaviza os picos de 100 cm/s)
    // Novo Valor = (Alfa * Valor Bruto Atual) + ((1 - Alfa) * Valor Antigo)
    gfVdirReal = (fAlfa * fVdirBruta) + ((1.0f - fAlfa) * gfVdirReal);
    gfVesqReal = (fAlfa * fVesqBruta) + ((1.0f - fAlfa) * gfVesqReal);

    // 4. Integração numérica para distância (CM) usa o valor já filtrado
    gfDistanciaDireitaCM  += (gfVdirReal * fDeltaT);
    gfDistanciaEsquerdaCM += (gfVesqReal * fDeltaT);

    osDelay(50);
  }
}

void task_LvBateria(void *argument) {
  /* Inicializa o ADC com DMA, AmpOp e os limites da bateria */
  vBatteryInit();

  for(;;) {
    // 1. Pega o valor calculado (em porcentagem) pela sua biblioteca
    uint16_t capBateria = usBatteryGetCharge();

    // 2. Guarda na variável global de forma protegida pelo Mutex dedicado
    if (Mutex_BatteryHandle != NULL) {
      osMutexAcquire(Mutex_BatteryHandle, osWaitForever);
      gu16BateriaPorcentagem = capBateria;
      osMutexRelease(Mutex_BatteryHandle);
    }

    osDelay(500); // Executa a cada 500ms
  }
}

void task_display(void *argument)
{
  /* USER CODE BEGIN testLCDTaskFunction */
  unsigned char ucLCDLine1Buff[17], ucLCDLine2Buff[17];
  uint16_t bat_local = 0;

  // Variáveis para converter o float em inteiro multiplicado por 10
  int32_t i32VesqMultiplicado = 0;
  int32_t i32VdirMultiplicado = 0;

  // Inicializa o display LCD
  lcdInit(&hi2c2, 0x27, 2, 16);

  /* Infinite loop */
  for(;;)
  {
    osDelay(500); // Atualiza a tela a cada 500ms

    // ---- 1. LEITURA PROTEGIDA DA BATERIA ----
    if (Mutex_BatteryHandle != NULL) {
      osMutexAcquire(Mutex_BatteryHandle, osWaitForever);
      bat_local = gu16BateriaPorcentagem;
      osMutexRelease(Mutex_BatteryHandle);
    }

    // ---- 2. TRATAMENTO MANUAL DO FLOAT (PONTO FIXO) ----
    // Exemplo: se gfVesqReal for 15.42f, v_multiplicado vira 154
    i32VesqMultiplicado = (int32_t)(gfVesqReal * 10.0f);
    i32VdirMultiplicado = (int32_t)(gfVdirReal * 10.0f);

    // Proteção contra valores negativos (caso a roda gire para trás)
    if (i32VesqMultiplicado < 0) i32VesqMultiplicado = 0;
    if (i32VdirMultiplicado < 0) i32VdirMultiplicado = 0;

    // ---- 3. ATUALIZA A BATERIA (Linha 0, Coluna 11) ----
    lcdSetCursorPosition(11, 0);
    sprintf((char*)ucLCDLine1Buff, "%3d%%", bat_local);
    lcdPrintStr(ucLCDLine1Buff, 4);

    // ---- 4. ATUALIZA OS ENCODERS USANDO APENAS INTEIROS (%d) ----
    // i32VesqMultiplicado / 10  -> Pega a parte inteira (ex: 154 / 10 = 15)
    // i32VesqMultiplicado % 10  -> Pega o resto / décimo (ex: 154 % 10 = 4)
    lcdSetCursorPosition(0, 1);
    sprintf((char*)ucLCDLine2Buff, "E:%2d.%1d  D:%2d.%1d ",
            (int)(i32VesqMultiplicado / 10), (int)(i32VesqMultiplicado % 10),
            (int)(i32VdirMultiplicado / 10), (int)(i32VdirMultiplicado % 10));

    lcdPrintStr(ucLCDLine2Buff, 16);
  }
  /* USER CODE END testLCDTaskFunction */
}
void task_Linhas(void *argument) {

    // Init da lib — uma única vez antes do loop
    vLineSensors_v2_Init(
        LINESENSORS_ADC_1, LINESENSORS_RANK_1,   // IR1 → LEFT
        LINESENSORS_ADC_2, LINESENSORS_RANK_1,   // IR2 → CENTER LEFT
        LINESENSORS_ADC_3, LINESENSORS_RANK_1,   // IR3 → CENTER
        LINESENSORS_ADC_4, LINESENSORS_RANK_1,   // IR4 → CENTER RIGHT
        LINESENSORS_ADC_5, LINESENSORS_RANK_1    // IR5 → RIGHT
    );

    for (;;) {
        // Lê posição interpolada da linha: -1.0 (esq) a +1.0 (dir)
        float fPos = fLineSensors_v2_GetInterpolatedValue();

        // Armazena no mutex para a task_Controle consumir
        osMutexAcquire(Mutex_SensoresHandle, osWaitForever);
        fPosicaoLinha = fPos;
        osMutexRelease(Mutex_SensoresHandle);

        osDelay(50);
    }
}

/* USER CODE END Application */
